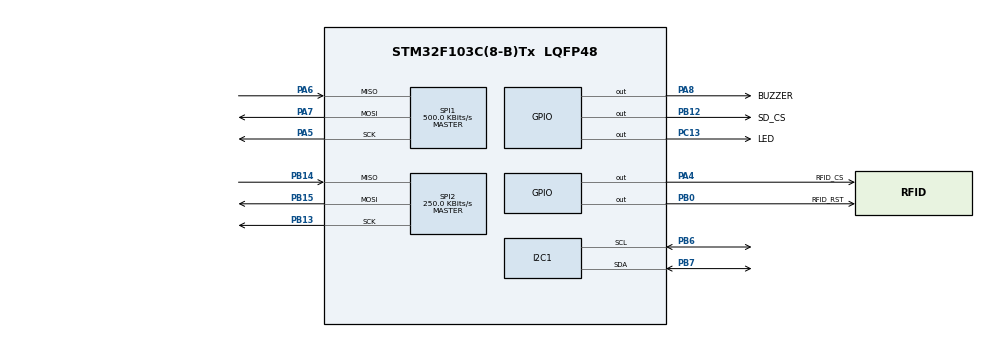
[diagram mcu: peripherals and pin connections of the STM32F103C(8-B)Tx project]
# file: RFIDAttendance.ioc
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Mcu.Family=STM32F1
Mcu.Name=STM32F103C(8-B)Tx
Mcu.Package=LQFP48
NVIC.PriorityGroup=NVIC_PRIORITYGROUP_4
PA13.Mode=Serial_Wire
PA13.Signal=SYS_JTMS-SWDIO
PA14.Mode=Serial_Wire
PA14.Signal=SYS_JTCK-SWCLK
PA4.GPIO_Label=RFID_CS
PA4.PinState=GPIO_PIN_SET
PA4.Signal=GPIO_Output
PA5.Mode=Full_Duplex_Master
PA5.Signal=SPI1_SCK
PA6.Mode=Full_Duplex_Master
PA6.Signal=SPI1_MISO
PA7.Mode=Full_Duplex_Master
PA7.Signal=SPI1_MOSI
PA8.GPIO_Label=BUZZER
PA8.Signal=GPIO_Output
PB0.GPIO_Label=RFID_RST
PB0.PinState=GPIO_PIN_SET
PB0.Signal=GPIO_Output
PB12.GPIO_Label=SD_CS
PB12.PinState=GPIO_PIN_SET
PB12.Signal=GPIO_Output
PB13.Mode=Full_Duplex_Master
PB13.Signal=SPI2_SCK
PB14.Mode=Full_Duplex_Master
PB14.Signal=SPI2_MISO
PB15.Mode=Full_Duplex_Master
PB15.Signal=SPI2_MOSI
PB6.Mode=I2C
PB6.Signal=I2C1_SCL
PB7.Mode=I2C
PB7.Signal=I2C1_SDA
PC13-TAMPER-RTC.GPIO_Label=LED
PC13-TAMPER-RTC.Signal=GPIO_Output
ProjectManager.HeapSize=0x200
ProjectManager.StackSize=0x400
ProjectManager.TargetToolchain=Makefile
RCC.APB1Freq_Value=8000000
RCC.APB2Freq_Value=8000000
SPI1.BaudRatePrescaler=SPI_BAUDRATEPRESCALER_16
SPI1.CalculateBaudRate=500.0 KBits/s
SPI1.Direction=SPI_DIRECTION_2LINES
SPI1.Mode=SPI_MODE_MASTER
SPI1.VirtualType=VM_MASTER
SPI2.BaudRatePrescaler=SPI_BAUDRATEPRESCALER_32
SPI2.CalculateBaudRate=250.0 KBits/s
SPI2.Direction=SPI_DIRECTION_2LINES
SPI2.Mode=SPI_MODE_MASTER
SPI2.VirtualType=VM_MASTER
board=custom

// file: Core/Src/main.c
/* USER CODE BEGIN Header */
/**
  ******************************************************************************
  * @file           : main.c
  * @brief          : Main program body
  ******************************************************************************
  * @attention
  *
  * Copyright (c) 2026 STMicroelectronics.
  * All rights reserved.
  *
  * This software is licensed under terms that can be found in the LICENSE file
  * in the root directory of this software component.
  * If no LICENSE file comes with this software, it is provided AS-IS.
  *
  ******************************************************************************
  */
/* USER CODE END Header */

#include "main.h"
#include "i2c.h"
#include "spi.h"
#include "gpio.h"

/* USER CODE BEGIN Includes */
#include "app.h"
#include "lcd_display.h"
/* USER CODE END Includes */

void SystemClock_Config(void);

int main(void)
{

  HAL_Init();

  SystemClock_Config();

  /* Initialize all configured peripherals */
  MX_GPIO_Init();
  MX_SPI1_Init();
  MX_I2C1_Init();
  MX_SPI2_Init();

  /* USER CODE BEGIN 2 */
  App_Init();
  Display_Init(HAL_GetTick());   /* LCD: hien MOI QUET THE */
  /* USER CODE END 2 */

  /* Infinite loop */
  while (1)
  {

    /* USER CODE BEGIN 3 */
    App_Process();
    {
      /* Lay ket qua cua App (moi lan quet) dua len LCD. Phai lay de App
       * nhan luot tiep theo, ke ca khi LCD dang loi. */
      DisplayEvent_t display;
      if (App_TakeDisplayEvent(&display)) {
        Display_Show(&display, HAL_GetTick());
      }
      Display_Process(HAL_GetTick());
    }
    HAL_Delay(5);
  }
  /* USER CODE END 3 */
}

void SystemClock_Config(void)
{
  RCC_OscInitTypeDef RCC_OscInitStruct = {0};
  RCC_ClkInitTypeDef RCC_ClkInitStruct = {0};

  RCC_OscInitStruct.OscillatorType = RCC_OSCILLATORTYPE_HSI;
  RCC_OscInitStruct.HSIState = RCC_HSI_ON;
  RCC_OscInitStruct.HSICalibrationValue = RCC_HSICALIBRATION_DEFAULT;
  RCC_OscInitStruct.PLL.PLLState = RCC_PLL_NONE;

  if (HAL_RCC_OscConfig(&RCC_OscInitStruct) != HAL_OK)
  {
    Error_Handler();
  }

  RCC_ClkInitStruct.ClockType = RCC_CLOCKTYPE_HCLK
                             | RCC_CLOCKTYPE_SYSCLK
                             | RCC_CLOCKTYPE_PCLK1
                             | RCC_CLOCKTYPE_PCLK2;

  RCC_ClkInitStruct.SYSCLKSource = RCC_SYSCLKSOURCE_HSI;
  RCC_ClkInitStruct.AHBCLKDivider = RCC_SYSCLK_DIV1;
  RCC_ClkInitStruct.APB1CLKDivider = RCC_HCLK_DIV1;
  RCC_ClkInitStruct.APB2CLKDivider = RCC_HCLK_DIV1;

  if (HAL_RCC_ClockConfig(&RCC_ClkInitStruct, FLASH_LATENCY_0) != HAL_OK)
  {
    Error_Handler();
  }
}

void Error_Handler(void)
{
  __disable_irq();
  while (1)
  {
  }
}

#ifdef USE_FULL_ASSERT
/**
  * @brief Reports the source file and line of an assert error.
  * @param file: source file name
  * @param line: source line number
  * @retval None
  */
void assert_failed(uint8_t *file, uint32_t line)
{
  /* USER CODE BEGIN 6 */

  (void)file;
  (void)line;

  /* USER CODE END 6 */
}
#endif /* USE_FULL_ASSERT */
